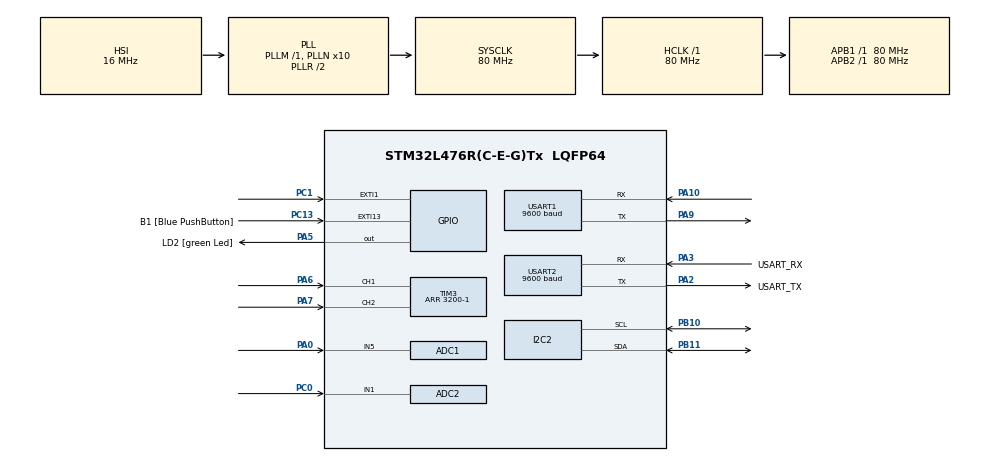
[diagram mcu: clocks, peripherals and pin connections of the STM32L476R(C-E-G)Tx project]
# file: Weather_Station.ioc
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ADC1.Channel-1\#ChannelRegularConversion=ADC_CHANNEL_5
ADC1.ContinuousConvMode=ENABLE
ADC1.EOCSelection=ADC_EOC_SINGLE_CONV
ADC1.NbrOfConversion=1
ADC1.NbrOfConversionFlag=1
ADC1.master=1
ADC2.Channel-0\#ChannelRegularConversion=ADC_CHANNEL_1
ADC2.ContinuousConvMode=ENABLE
ADC2.NbrOfConversionFlag=1
ADC2.OffsetNumber-0\#ChannelRegularConversion=ADC_OFFSET_NONE
ADC2.Rank-0\#ChannelRegularConversion=1
ADC2.SamplingTime-0\#ChannelRegularConversion=ADC_SAMPLETIME_2CYCLES_5
FREERTOS.Tasks01=defaultTask,0,128,StartDefaultTask,Default,NULL,Dynamic,NULL,NULL;IHM_Task,-3,512,Start_IHM_Task,As weak,NULL,Dynamic,NULL,NULL;GPS_Task,-3,512,Start_GPS_Task,As weak,NULL,Dynamic,NULL,NULL;SatellitePredic,-3,1024,Start_SatellitePrediction_Task,As weak,NULL,Dynamic,NULL,NULL;Sensors_Task,-3,512,Start_Sensors_Task,As weak,NULL,Dynamic,NULL,NULL;MonitorTask,-3,256,StartMonitorTask,Default,NULL,Dynamic,NULL,NULL;Lora_Task,-3,512,Start_Lora_Task,As weak,NULL,Dynamic,NULL,NULL
FREERTOS.configTOTAL_HEAP_SIZE=20000
FREERTOS.configUSE_NEWLIB_REENTRANT=1
FREERTOS.configUSE_TIMERS=1
I2C2.Timing=0x10D19CE4
Mcu.Family=STM32L4
Mcu.Name=STM32L476R(C-E-G)Tx
Mcu.Package=LQFP64
NVIC.EXTI1_IRQn=true\:5\:0\:false\:false\:true\:true\:true\:true\:true
NVIC.I2C2_ER_IRQn=true\:5\:0\:false\:false\:true\:true\:true\:true\:true
NVIC.I2C2_EV_IRQn=true\:5\:0\:false\:false\:true\:true\:true\:true\:true
NVIC.PriorityGroup=NVIC_PRIORITYGROUP_4
NVIC.TIM2_IRQn=true\:5\:0\:false\:false\:true\:true\:true\:true\:true
NVIC.TIM6_DAC_IRQn=true\:15\:0\:false\:false\:true\:false\:false\:true\:true
NVIC.TimeBase=TIM6_DAC_IRQn
NVIC.TimeBaseIP=TIM6
NVIC.USART1_IRQn=true\:5\:0\:false\:false\:true\:true\:true\:true\:true
NVIC.USART2_IRQn=true\:5\:0\:false\:false\:true\:true\:true\:true\:true
PA0.Signal=ADCx_IN5
PA10.Mode=Asynchronous
PA10.Signal=USART1_RX
PA13\ (JTMS-SWDIO).GPIO_Label=TMS
PA13\ (JTMS-SWDIO).Mode=Serial_Wire
PA13\ (JTMS-SWDIO).Signal=SYS_JTMS-SWDIO
PA14\ (JTCK-SWCLK).GPIO_Label=TCK
PA14\ (JTCK-SWCLK).Mode=Serial_Wire
PA14\ (JTCK-SWCLK).Signal=SYS_JTCK-SWCLK
PA2.GPIO_Label=USART_TX
PA2.GPIO_Mode=GPIO_MODE_AF_PP
PA2.GPIO_PuPd=GPIO_NOPULL
PA2.GPIO_Speed=GPIO_SPEED_FREQ_VERY_HIGH
PA2.Mode=Asynchronous
PA2.Signal=USART2_TX
PA3.GPIO_Label=USART_RX
PA3.GPIO_Mode=GPIO_MODE_AF_PP
PA3.GPIO_PuPd=GPIO_NOPULL
PA3.GPIO_Speed=GPIO_SPEED_FREQ_VERY_HIGH
PA3.Mode=Asynchronous
PA3.Signal=USART2_RX
PA5.GPIO_Label=LD2 [green Led]
PA5.GPIO_ModeDefaultOutputPP=GPIO_MODE_OUTPUT_PP
PA5.GPIO_PuPd=GPIO_NOPULL
PA5.GPIO_Speed=GPIO_SPEED_FREQ_LOW
PA5.Signal=GPIO_Output
PA6.Signal=S_TIM3_CH1
PA7.Signal=S_TIM3_CH2
PA9.Mode=Asynchronous
PA9.Signal=USART1_TX
PB10.Mode=I2C
PB10.Signal=I2C2_SCL
PB11.Mode=I2C
PB11.Signal=I2C2_SDA
PB3\ (JTDO-TRACESWO).GPIO_Label=SWO
PB3\ (JTDO-TRACESWO).Signal=SYS_JTDO-SWO
PC0.Signal=ADCx_IN1
PC1.GPIO_PuPd=GPIO_PULLDOWN
PC1.Signal=GPXTI1
PC13.GPIO_Label=B1 [Blue PushButton]
PC13.GPIO_ModeDefaultEXTI=GPIO_MODE_IT_FALLING
PC13.GPIO_PuPd=GPIO_NOPULL
PC13.Signal=GPXTI13
PC14-OSC32_IN\ (PC14).Mode=LSE-External-Oscillator
PC14-OSC32_IN\ (PC14).Signal=RCC_OSC32_IN
PC15-OSC32_OUT\ (PC15).Mode=LSE-External-Oscillator
PC15-OSC32_OUT\ (PC15).Signal=RCC_OSC32_OUT
PH0-OSC_IN\ (PH0).Mode=HSE-External-Oscillator
PH0-OSC_IN\ (PH0).Signal=RCC_OSC_IN
PH1-OSC_OUT\ (PH1).Mode=HSE-External-Oscillator
PH1-OSC_OUT\ (PH1).Signal=RCC_OSC_OUT
ProjectManager.HeapSize=0x200
ProjectManager.StackSize=0x400
ProjectManager.TargetToolchain=STM32CubeIDE
RCC.ADCFreq_Value=64000000
RCC.AHBFreq_Value=80000000
RCC.APB1Freq_Value=80000000
RCC.APB1TimFreq_Value=80000000
RCC.APB2Freq_Value=80000000
RCC.APB2TimFreq_Value=80000000
RCC.CortexFreq_Value=80000000
RCC.HCLKFreq_Value=80000000
RCC.HSE_VALUE=8000000
RCC.HSI_VALUE=16000000
RCC.MSI_VALUE=4000000
RCC.PLLN=10
RCC.PLLSourceVirtual=RCC_PLLSOURCE_HSI
RCC.PREFETCH_ENABLE=1
RCC.SYSCLKFreq_VALUE=80000000
RCC.SYSCLKSource=RCC_SYSCLKSOURCE_PLLCLK
RCC.USBFreq_Value=64000000
RCC.VCOOutputFreq_Value=160000000
RTC.Alarm-Alarm\ A=RTC_ALARM_A
RTC.Date=3
RTC.Format=RTC_FORMAT_BIN
RTC.Hours=16
RTC.Minutes=27
RTC.Month=RTC_MONTH_JUNE
RTC.Seconds=30
RTC.WeekDay=RTC_WEEKDAY_TUESDAY
RTC.Year=25
SH.ADCx_IN1.0=ADC2_IN1,IN1-Single-Ended
SH.ADCx_IN5.0=ADC1_IN5,IN5-Single-Ended
SH.S_TIM3_CH1.0=TIM3_CH1,Encoder_Interface
SH.S_TIM3_CH2.0=TIM3_CH2,Encoder_Interface
TIM2.Period=160-1
TIM2.Prescaler=10000-1
TIM3.EncoderMode=TIM_ENCODERMODE_TI12
TIM3.IC1Polarity=TIM_ICPOLARITY_FALLING
TIM3.IC2Polarity=TIM_ICPOLARITY_FALLING
TIM3.Period=3200-1
USART1.BaudRate=9600
USART1.Mode=MODE_RX
USART1.VirtualMode-Asynchronous=VM_ASYNC
USART2.BaudRate=9600
USART2.VirtualMode-Asynchronous=VM_ASYNC
VP_FREERTOS_VS_CMSIS_V1.Mode=CMSIS_V1
VP_RTC_VS_RTC_Activate.Mode=RTC_Enabled
VP_RTC_VS_RTC_Alarm_A_Intern.Mode=Alarm A
VP_RTC_VS_RTC_Calendar.Mode=RTC_Calendar
VP_SYS_VS_tim6.Mode=TIM6
VP_TIM2_VS_ClockSourceINT.Mode=Internal
board=NUCLEO-L476RG

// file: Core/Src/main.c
/* USER CODE BEGIN Header */
/**
  ******************************************************************************
  * @file           : main.c
  * @brief          : Main program body
  ******************************************************************************
  * @attention
  *
  * Copyright (c) 2025 STMicroelectronics.
  * All rights reserved.
  *
  * This software is licensed under terms that can be found in the LICENSE file
  * in the root directory of this software component.
  * If no LICENSE file comes with this software, it is provided AS-IS.
  *
  ******************************************************************************
  */
/* USER CODE END Header */
#include "main.h"
#include "cmsis_os.h"
#include "adc.h"
#include "i2c.h"
#include "rtc.h"
#include "tim.h"
#include "usart.h"
#include "gpio.h"

/* USER CODE BEGIN PV */
uint8_t Reset_Flag=0;
/* USER CODE END PV */

void SystemClock_Config(void);
void PeriphCommonClock_Config(void);
void MX_FREERTOS_Init(void);

/* USER CODE BEGIN 0 */
volatile uint8_t debounce_active = 0;
volatile uint8_t valid_press = 0;
/* USER CODE END 0 */

int main(void)
{

  /* MCU Configuration--------------------------------------------------------*/

  /* Reset of all peripherals, Initializes the Flash interface and the Systick. */
  HAL_Init();

  /* Configure the system clock */
  SystemClock_Config();

  /* Configure the peripherals common clocks */
  PeriphCommonClock_Config();

  /* Initialize all configured peripherals */
  MX_GPIO_Init();
  MX_USART2_UART_Init();
  MX_RTC_Init();
  MX_USART1_UART_Init();
  MX_ADC1_Init();
  MX_I2C2_Init();
  MX_ADC2_Init();
  MX_TIM2_Init();
  MX_TIM3_Init();
  /* USER CODE BEGIN 2 */
  Reset_Flag=1;
  /* USER CODE END 2 */

  /* Call init function for freertos objects (in cmsis_os2.c) */
  MX_FREERTOS_Init();

  /* Start scheduler */
  osKernelStart();

  /* We should never get here as control is now taken by the scheduler */

  /* Infinite loop */
  while (1)
  {

  }
}

void SystemClock_Config(void)
{
  RCC_OscInitTypeDef RCC_OscInitStruct = {0};
  RCC_ClkInitTypeDef RCC_ClkInitStruct = {0};

  /** Configure the main internal regulator output voltage
  */
  if (HAL_PWREx_ControlVoltageScaling(PWR_REGULATOR_VOLTAGE_SCALE1) != HAL_OK)
  {
    Error_Handler();
  }

  /** Initializes the RCC Oscillators according to the specified parameters
  * in the RCC_OscInitTypeDef structure.
  */
  RCC_OscInitStruct.OscillatorType = RCC_OSCILLATORTYPE_HSI|RCC_OSCILLATORTYPE_LSI;
  RCC_OscInitStruct.HSIState = RCC_HSI_ON;
  RCC_OscInitStruct.HSICalibrationValue = RCC_HSICALIBRATION_DEFAULT;
  RCC_OscInitStruct.LSIState = RCC_LSI_ON;
  RCC_OscInitStruct.PLL.PLLState = RCC_PLL_ON;
  RCC_OscInitStruct.PLL.PLLSource = RCC_PLLSOURCE_HSI;
  RCC_OscInitStruct.PLL.PLLM = 1;
  RCC_OscInitStruct.PLL.PLLN = 10;
  RCC_OscInitStruct.PLL.PLLP = RCC_PLLP_DIV7;
  RCC_OscInitStruct.PLL.PLLQ = RCC_PLLQ_DIV2;
  RCC_OscInitStruct.PLL.PLLR = RCC_PLLR_DIV2;
  if (HAL_RCC_OscConfig(&RCC_OscInitStruct) != HAL_OK)
  {
    Error_Handler();
  }

  /** Initializes the CPU, AHB and APB buses clocks
  */
  RCC_ClkInitStruct.ClockType = RCC_CLOCKTYPE_HCLK|RCC_CLOCKTYPE_SYSCLK
                              |RCC_CLOCKTYPE_PCLK1|RCC_CLOCKTYPE_PCLK2;
  RCC_ClkInitStruct.SYSCLKSource = RCC_SYSCLKSOURCE_PLLCLK;
  RCC_ClkInitStruct.AHBCLKDivider = RCC_SYSCLK_DIV1;
  RCC_ClkInitStruct.APB1CLKDivider = RCC_HCLK_DIV1;
  RCC_ClkInitStruct.APB2CLKDivider = RCC_HCLK_DIV1;

  if (HAL_RCC_ClockConfig(&RCC_ClkInitStruct, FLASH_LATENCY_4) != HAL_OK)
  {
    Error_Handler();
  }
}

void PeriphCommonClock_Config(void)
{
  RCC_PeriphCLKInitTypeDef PeriphClkInit = {0};

  /** Initializes the peripherals clock
  */
  PeriphClkInit.PeriphClockSelection = RCC_PERIPHCLK_ADC;
  PeriphClkInit.AdcClockSelection = RCC_ADCCLKSOURCE_PLLSAI1;
  PeriphClkInit.PLLSAI1.PLLSAI1Source = RCC_PLLSOURCE_HSI;
  PeriphClkInit.PLLSAI1.PLLSAI1M = 1;
  PeriphClkInit.PLLSAI1.PLLSAI1N = 8;
  PeriphClkInit.PLLSAI1.PLLSAI1P = RCC_PLLP_DIV7;
  PeriphClkInit.PLLSAI1.PLLSAI1Q = RCC_PLLQ_DIV2;
  PeriphClkInit.PLLSAI1.PLLSAI1R = RCC_PLLR_DIV2;
  PeriphClkInit.PLLSAI1.PLLSAI1ClockOut = RCC_PLLSAI1_ADC1CLK;
  if (HAL_RCCEx_PeriphCLKConfig(&PeriphClkInit) != HAL_OK)
  {
    Error_Handler();
  }
}

void HAL_TIM_PeriodElapsedCallback(TIM_HandleTypeDef *htim)
{
  if (htim->Instance == TIM6)
  {
    HAL_IncTick();
  }
  /* USER CODE BEGIN Callback 1 */
  if (htim->Instance == TIM2)
  	{
  		HAL_TIM_Base_Stop_IT(&htim2);
  		debounce_active = 0;

  		if (HAL_GPIO_ReadPin(GPIOC, GPIO_PIN_1) == GPIO_PIN_SET)
  		{
  			valid_press = 1;
  		}
  	}
  /* USER CODE END Callback 1 */
}

void Error_Handler(void)
{
  __disable_irq();
  while (1)
  {
  }
}

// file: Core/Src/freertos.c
/* USER CODE BEGIN Header */
/**
 ******************************************************************************
 * File Name          : freertos.c
 * Description        : Code for freertos applications
 ******************************************************************************
 * @attention
 *
 * Copyright (c) 2025 STMicroelectronics.
 * All rights reserved.
 *
 * This software is licensed under terms that can be found in the LICENSE file
 * in the root directory of this software component.
 * If no LICENSE file comes with this software, it is provided AS-IS.
 *
 ******************************************************************************
 */
/* USER CODE END Header */

#include "FreeRTOS.h"
#include "task.h"
#include "main.h"
#include "cmsis_os.h"

/* USER CODE BEGIN Includes */
#include "mygps.h"
#include "portable.h" // Pour xPortGetFreeHeapSize()
/* USER CODE END Includes */

/* USER CODE BEGIN Variables */
xQueueHandle GpsToIhm;
/* USER CODE END Variables */
osThreadId defaultTaskHandle;
osThreadId IHM_TaskHandle;
osThreadId GPS_TaskHandle;
osThreadId SatellitePredicHandle;
osThreadId Sensors_TaskHandle;
osThreadId MonitorTaskHandle;
osThreadId Lora_TaskHandle;

void StartDefaultTask(void const * argument);
void Start_IHM_Task(void const * argument);
void Start_GPS_Task(void const * argument);
void Start_SatellitePrediction_Task(void const * argument);
void Start_Sensors_Task(void const * argument);
void StartMonitorTask(void const * argument);
void Start_Lora_Task(void const * argument);

void MX_FREERTOS_Init(void); /* (MISRA C 2004 rule 8.1) */

/* GetIdleTaskMemory prototype (linked to static allocation support) */
void vApplicationGetIdleTaskMemory( StaticTask_t **ppxIdleTaskTCBBuffer, StackType_t **ppxIdleTaskStackBuffer, uint32_t *pulIdleTaskStackSize );

/* GetTimerTaskMemory prototype (linked to static allocation support) */
void vApplicationGetTimerTaskMemory( StaticTask_t **ppxTimerTaskTCBBuffer, StackType_t **ppxTimerTaskStackBuffer, uint32_t *pulTimerTaskStackSize );

/* USER CODE BEGIN GET_IDLE_TASK_MEMORY */
static StaticTask_t xIdleTaskTCBBuffer;
static StackType_t xIdleStack[configMINIMAL_STACK_SIZE];

void vApplicationGetIdleTaskMemory( StaticTask_t **ppxIdleTaskTCBBuffer, StackType_t **ppxIdleTaskStackBuffer, uint32_t *pulIdleTaskStackSize )
{
	*ppxIdleTaskTCBBuffer = &xIdleTaskTCBBuffer;
	*ppxIdleTaskStackBuffer = &xIdleStack[0];
	*pulIdleTaskStackSize = configMINIMAL_STACK_SIZE;
	/* place for user code */
}
/* USER CODE END GET_IDLE_TASK_MEMORY */

/* USER CODE BEGIN GET_TIMER_TASK_MEMORY */
static StaticTask_t xTimerTaskTCBBuffer;
static StackType_t xTimerStack[configTIMER_TASK_STACK_DEPTH];

void vApplicationGetTimerTaskMemory( StaticTask_t **ppxTimerTaskTCBBuffer, StackType_t **ppxTimerTaskStackBuffer, uint32_t *pulTimerTaskStackSize )
{
	*ppxTimerTaskTCBBuffer = &xTimerTaskTCBBuffer;
	*ppxTimerTaskStackBuffer = &xTimerStack[0];
	*pulTimerTaskStackSize = configTIMER_TASK_STACK_DEPTH;
	/* place for user code */
}
/* USER CODE END GET_TIMER_TASK_MEMORY */

void MX_FREERTOS_Init(void) {

  /* USER CODE BEGIN RTOS_MUTEX */
	/*SimpleMutex = xSemaphoreCreateMutex();

	if (SimpleMutex != NULL)
	{
	 HAL_UART_Transmit(&huart2, "Mutex Created\n\n", 15, 1000);
	}*/
  /* USER CODE END RTOS_MUTEX */

  /* USER CODE BEGIN RTOS_QUEUES */
	GpsToIhm=xQueueCreate(10,sizeof(GPS_IHM));
  /* USER CODE END RTOS_QUEUES */

  /* Create the thread(s) */
  /* definition and creation of defaultTask */
  osThreadDef(defaultTask, StartDefaultTask, osPriorityNormal, 0, 128);
  defaultTaskHandle = osThreadCreate(osThread(defaultTask), NULL);

  /* definition and creation of IHM_Task */
  osThreadDef(IHM_Task, Start_IHM_Task, osPriorityIdle, 0, 512);
  IHM_TaskHandle = osThreadCreate(osThread(IHM_Task), NULL);

  /* definition and creation of GPS_Task */
  osThreadDef(GPS_Task, Start_GPS_Task, osPriorityIdle, 0, 512);
  GPS_TaskHandle = osThreadCreate(osThread(GPS_Task), NULL);

  /* definition and creation of SatellitePredic */
  osThreadDef(SatellitePredic, Start_SatellitePrediction_Task, osPriorityIdle, 0, 1024);
  SatellitePredicHandle = osThreadCreate(osThread(SatellitePredic), NULL);

  /* definition and creation of Sensors_Task */
  osThreadDef(Sensors_Task, Start_Sensors_Task, osPriorityIdle, 0, 512);
  Sensors_TaskHandle = osThreadCreate(osThread(Sensors_Task), NULL);

  /* definition and creation of MonitorTask */
  osThreadDef(MonitorTask, StartMonitorTask, osPriorityIdle, 0, 256);
  MonitorTaskHandle = osThreadCreate(osThread(MonitorTask), NULL);

  /* definition and creation of Lora_Task */
  osThreadDef(Lora_Task, Start_Lora_Task, osPriorityIdle, 0, 512);
  Lora_TaskHandle = osThreadCreate(osThread(Lora_Task), NULL);

}

void StartDefaultTask(void const * argument)
{
	for(;;)
	{
		osDelay(1);
	}
}

__weak void Start_IHM_Task(void const * argument)
{
	for(;;)
	{
		osDelay(1);
	}
}

__weak void Start_GPS_Task(void const * argument)
{
	for(;;)
	{
		osDelay(1);
	}
}

__weak void Start_SatellitePrediction_Task(void const * argument)
{
	for(;;)
	{
		osDelay(1);
	}
}

__weak void Start_Sensors_Task(void const * argument)
{
	for(;;)
	{
		osDelay(1);
	}
}

void StartMonitorTask(void const * argument)
{
  /* USER CODE BEGIN StartMonitorTask */
//	char buf[200];

	for(;;)
	{
		/*sprintf(buf,
			    "Stack: GPS=%lu B | IHM=%lu B |Satellite_predict=%lu B |Sensors=%lu B | Heap Left=%lu B \r\n LORA =%lu ",
				uxTaskGetStackHighWaterMark(GPS_TaskHandle) ,
				uxTaskGetStackHighWaterMark(IHM_TaskHandle),uxTaskGetStackHighWaterMark(SatellitePredicHandle),
				uxTaskGetStackHighWaterMark(Sensors_TaskHandle) ,
				(unsigned long)xPortGetFreeHeapSize(),uxTaskGetStackHighWaterMark(Lora_TaskHandle));

		HAL_UART_Transmit(&huart2, (uint8_t*)buf, strlen(buf), HAL_MAX_DELAY);
*/
		osDelay(10);
	}
  /* USER CODE END StartMonitorTask */
}

__weak void Start_Lora_Task(void const * argument)
{
  for(;;)
  {
    osDelay(1);
  }
}

/* USER CODE BEGIN Application */
/*void SendUart(uint8_t *str)
{
xSemaphoreTake(SimpleMutex,portMAX_DELAY);
HAL_Delay(2000);
HAL_UART_Transmit(&huart2,str, strlen((char*)str), 100);
xSemaphoreGive(SimpleMutex);
}*/
/* USER CODE END Application */
